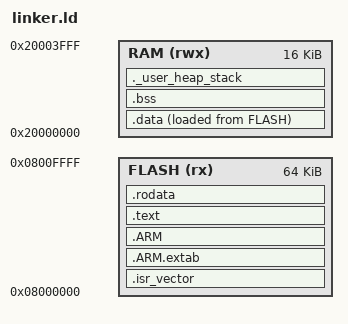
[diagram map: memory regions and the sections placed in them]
/*
    This exists because an OS like windows has a loader that assigns addresses at launch
    On baremetal systems, we need to define the memory layout manually
*/

/* Linker script for baremetal systems */

/* Entry Point */
ENTRY(Reset_Handler)

/* Highest address of the user mode stack */
_estack = ORIGIN(RAM) + LENGTH(RAM); /* end of "RAM" Ram type memory */

MEMORY
{
    /* Define the memory regions */
    FLASH (rx) : ORIGIN = 0x08000000, LENGTH = 64K
    RAM (rwx) : ORIGIN = 0x20000000, LENGTH = 16K
}

/* Sections */
SECTIONS
{   
    /* comes first so that the vector table can be used right away with no garbage */
    /* The startup code into "FLASH" Rom type memory */
    .isr_vector : 
    {
        . = ALIGN(4);
        KEEP(*(.isr_vector)) /* Startup code */
        . = ALIGN(4);
    } >FLASH

    .ARM.extab : 
    {
        . = ALIGN(4);
        *(.ARM.extab* .gnu.linkonce.armextab.*)
        . = ALIGN(4);
    } >FLASH

    .ARM :
    {
        . = ALIGN(4);
        __exidx_start = .;
        *(.ARM.exidx*)
        __exidx_end = .;
        . = ALIGN(4);
    } >FLASH

    .text :
    {
        . = ALIGN(4);
        *(.text)           /* .text sections (code) */
        *(.text*)          /* .text* sections (code) */

        . = ALIGN(4);
        _etext = .;        /* define a global symbols at end of code */
    } >FLASH

    /* Constant data into "FLASH" Rom type memory */
    .rodata :
    {
        . = ALIGN(4);
        *(.rodata)         /* .rodata sections (constants, strings, etc.) */
        *(.rodata*)        /* .rodata* sections (constants, strings, etc.) */
        . = ALIGN(4);
    } >FLASH

    /* Used by the startup to initialize data */
    _sidata = LOADADDR(.data);

    /* Initialized data sections into "RAM" Ram type memory */
    .data :
    {
        . = ALIGN(4);
        _sdata = .;        /* create a global symbol at data start */
        *(.data)           /* .data sections */
        *(.data*)          /* .data* sections */

        . = ALIGN(4);
        _edata = .;        /* define a global symbol at data end */

    } >RAM AT> FLASH

    /* Uninitialized data section into "RAM" Ram type memory */
    . = ALIGN(4);
    .bss :
    {
        /* This is used by the startup in order to initialize the .bss section */
        _sbss = .;         /* define a global symbol at bss start */
        *(.bss)
        *(.bss*)
        *(COMMON)

        . = ALIGN(4);
        _ebss = .;         /* define a global symbol at bss end */
    } >RAM

    /* 
        RAM grows upwards, Stack grows downwards and heap 
        grows upwards. and so if the heap and stack grow
        big enough they will eventually collide and eat each
        other. Nothing to stop that from happening. so this
        code blocks out 1000 bytes of ram so if this collision
        happens, the linker will complain. 
    */ 

    _Min_Heap_Size  = 0x0;    /* no malloc in this kernel */
    _Min_Stack_Size = 0x400;  /* 1 KB for MSP */

    ._user_heap_stack :
    {
        . = ALIGN(8);
        PROVIDE ( end = . );
        PROVIDE ( _end = . );
        . = . + _Min_Heap_Size;
        . = . + _Min_Stack_Size;
        . = ALIGN(8);
    } >RAM
}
